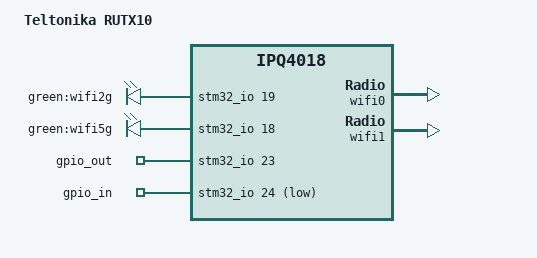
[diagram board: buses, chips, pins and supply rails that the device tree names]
// SPDX-License-Identifier: GPL-2.0-or-later OR MIT

#include "qcom-ipq4018-rutx-stm32.dtsi"

/ {
	model = "Teltonika RUTX10";
	compatible = "teltonika,rutx10";

	soc {
		leds {
			compatible = "gpio-leds";

			wifi2g {
				label = "green:wifi2g";
				gpios = <&stm32_io 19 GPIO_ACTIVE_HIGH>;
				linux,default-trigger = "phy0tpt";
			};

			wifi5g {
				label = "green:wifi5g";
				gpios = <&stm32_io 18 GPIO_ACTIVE_HIGH>;
				linux,default-trigger = "phy1tpt";
			};
		};

		gpio_export {
			compatible = "gpio-export";
			#size-cells = <0>;

			gpio_out {
				gpio-export,name = "gpio_out";
				gpio-export,output = <0>;
				gpio-export,direction_may_change = <0>;
				gpios = <&stm32_io 23 GPIO_ACTIVE_HIGH>;
			};

			gpio_in {
				gpio-export,name = "gpio_in";
				gpio-export,input = <0>;
				gpio-export,direction_may_change = <0>;
				gpios = <&stm32_io 24 GPIO_ACTIVE_LOW>;
			};
		};
	};
};

&wifi0 {
	status = "okay";
	qcom,ath10k-calibration-variant = "Teltonika-RUTX10";
};

&wifi1 {
	status = "okay";
	qcom,ath10k-calibration-variant = "Teltonika-RUTX10";
};
